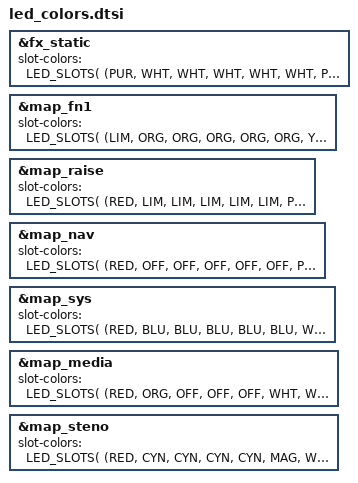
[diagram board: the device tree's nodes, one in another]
/*
 * Cores de cada LED em cada camada (zmk-rgb-matrix, efeito "static").
 *
 * Este arquivo e incluido no final de corne.keymap. Cada bloco "&map_<camada>"
 * preenche o slot-colors do efeito static de uma camada: o de um overlay de
 * camada (FN1 a STENO, cobrem os 27 LEDs de cada metade enquanto a camada esta
 * ativa) ou o do efeito fx_static (mapa da camada base, QWERTY). A estrutura
 * (overlays, condicoes, efeitos e o layer-id de cada mapa) fica em
 * corne.keymap; aqui ficam so as cores.
 *
 * Estas sao as cores PADRAO, as que o firmware tem de fabrica. O firmware
 * deixa editar e salvar as cores de cada slot no teclado (ZMK Studio, com o
 * fork lenerdz/zmk-studio-messages): o que for salvo vale no lugar destas, so
 * nos slots alterados, e RGB_RESET volta tudo para o que esta escrito aqui.
 *
 * COMO EDITAR
 *   Troque o nome da cor de uma posicao. Cada metade tem 3 linhas de 6 teclas,
 *   os 3 polegares e os 6 LEDs de underglow, nesta ordem:
 *
 *     esquerda:   0  1  2  3  4  5       direita:   6  7  8  9 10 11
 *                12 13 14 15 16 17                 18 19 20 21 22 23
 *                24 25 26 27 28 29                 30 31 32 33 34 35
 *                         36 37 38                 39 40 41
 *
 *   OFF apaga o LED. O comentario ao lado de cada linha diz que tecla era
 *   aquela no keymap quando o mapa foi escrito (se mudar a tecla, atualize a
 *   cor e o comentario).
 *
 * REGRAS
 *   - Dentro de LED_SLOTS(...) use so comentarios do tipo barra-asterisco. Um
 *     comentario de duas barras engole o resto da linha depois do pre-processador
 *     e apaga cores sem avisar.
 *   - O primeiro grupo e o das teclas da esquerda e o segundo o das teclas da
 *     direita. Os grupos tem sempre 27 valores (21 teclas + 6 de underglow).
 *   - As cores sao 0xRRGGBB com brilho cheio. O brilho real vem do kprgb
 *     (RGB_BRI e RGB_BRD, max-brightness) e vale para todas as cores igualmente.
 */

/*
 * Paleta. Para criar uma cor nova, acrescente uma linha (nome e 0xRRGGBB).
 */
#define OFF 0x000000 /* apagado */
#define WHT 0xFFFFFF /* branco */
#define RED 0xFF0000 /* vermelho */
#define ORG 0xFF8000 /* laranja */
#define YEL 0xFFFF00 /* amarelo */
#define LIM 0x80FF00 /* verde-limao */
#define GRN 0x00FF00 /* verde */
#define TEA 0x00FF80 /* verde-agua */
#define CYN 0x00FFFF /* ciano */
#define SKY 0x0080FF /* azul-claro */
#define BLU 0x0000FF /* azul */
#define PUR 0x8000FF /* roxo */
#define MAG 0xFF00FF /* magenta */
#define PNK 0xFF0080 /* rosa */

/*
 * Slots (a posicao de cada cor na lista slot-colors, 0 a 53). Sao os mesmos
 * nas duas metades, por isso a mesma lista vale para as duas:
 *   0 a 41  : a tecla de mesma posicao no keymap (k0 a k41)
 *   42 a 47 : underglow da esquerda (u0 a u5, na ordem da fita da esquerda)
 *   48 a 53 : underglow da direita (u0 a u5, na ordem da fita da direita)
 * "no-key-slots" e "slot-count" de corne_left.overlay e corne_right.overlay
 * dizem ao firmware qual LED usa qual slot.
 *
 * LED_SLOTS(esquerda, direita) recebe os dois grupos como estao escritos nos
 * blocos abaixo (cada um com 27 cores, na ordem dos parametros de
 * LED_SLOT_ORDER) e devolve as 54 cores na ordem dos slots.
 */
#define LED_UNPAREN(...) __VA_ARGS__
#define LED_APPLY(macro, ...) macro(__VA_ARGS__)
#define LED_SLOTS(left, right)                                                 \
    LED_APPLY(LED_SLOT_ORDER, LED_UNPAREN left, LED_UNPAREN right)

#define LED_SLOT_ORDER(                                                        \
    k0,  k1,  k2,  k3,  k4,  k5,                                               \
    k12, k13, k14, k15, k16, k17,                                              \
    k24, k25, k26, k27, k28, k29,                                              \
                   k36, k37, k38,                                              \
    l0,  l1,  l2,  l3,  l4,  l5,                                               \
    k6,  k7,  k8,  k9,  k10, k11,                                              \
    k18, k19, k20, k21, k22, k23,                                              \
    k30, k31, k32, k33, k34, k35,                                              \
    k39, k40, k41,                                                             \
    r0,  r1,  r2,  r3,  r4,  r5)                                               \
    k0  k1  k2  k3  k4  k5  k6  k7  k8  k9  k10 k11                            \
    k12 k13 k14 k15 k16 k17 k18 k19 k20 k21 k22 k23                            \
    k24 k25 k26 k27 k28 k29 k30 k31 k32 k33 k34 k35                            \
    k36 k37 k38 k39 k40 k41                                                    \
    l0  l1  l2  l3  l4  l5  r0  r1  r2  r3  r4  r5


/* Camada 0: QWERTY (destaque BLU) */
&fx_static {
    slot-colors = <LED_SLOTS(
        /* esquerda */
        (PUR, WHT, WHT, WHT, WHT, WHT, /* TAB Q W E R T */
         PUR, WHT, WHT, WHT, WHT, WHT, /* LSHFT A S D F G */
         PUR, WHT, WHT, WHT, WHT, WHT, /* LCTRL Z X C V B */
                        PUR, ORG, WHT, /* LGUI FN1 SPACE (polegares) */
         BLU, BLU, BLU, BLU, BLU, BLU)/* underglow */,

        /* direita */
        (WHT, WHT, WHT, WHT, WHT, RED, /* Y U I O P BSPC */
         WHT, WHT, WHT, WHT, LIM, LIM, /* H J K L SEMI SQT */
         WHT, WHT, LIM, LIM, SKY, SKY, /* N M COMMA DOT LBKT RBKT */
         TEA, SKY, PUR, /* RET RAISE RALT (polegares) */
         BLU, BLU, BLU, BLU, BLU, BLU)/* underglow */
    )>;
};

/* Camada 1: FN1 (destaque ORG) */
&map_fn1 {
    slot-colors = <LED_SLOTS(
        /* esquerda */
        (LIM, ORG, ORG, ORG, ORG, ORG, /* GRAVE F1 F2 F3 F4 F5 */
         YEL, YEL, YEL, YEL, YEL, YEL, /* N1 N2 N3 N4 N5 N6 */
         GRN, MAG, CYN, ORG, OFF, OFF, /* NAV SYS MEDIA F12 -- -- */
                        PUR, ORG, WHT, /* LGUI -- SPACE (polegares) */
         ORG, ORG, ORG, ORG, ORG, ORG)/* underglow */,

        /* direita */
        (ORG, ORG, ORG, ORG, ORG, ORG, /* F6 F7 F8 F9 F10 F11 */
         YEL, YEL, YEL, YEL, LIM, LIM, /* N7 N8 N9 N0 MINUS EQUAL */
         OFF, OFF, OFF, OFF, OFF, OFF, /* -- -- -- -- -- -- */
         TEA, SKY, PUR, /* RET -- RALT (polegares) */
         ORG, ORG, ORG, ORG, ORG, ORG)/* underglow */
    )>;
};

/* Camada 2: RAISE (destaque SKY) */
&map_raise {
    slot-colors = <LED_SLOTS(
        /* esquerda */
        (RED, LIM, LIM, LIM, LIM, LIM, /* ESC EXCL AT HASH DLLR PRCNT */
         PUR, MAG, LIM, LIM, LIM, LIM, /* LCTRL STUDIO FSLH BSLH GRAVE TILDE */
         PUR, OFF, OFF, OFF, OFF, OFF, /* LSHFT -- -- -- -- -- */
                        PUR, ORG, WHT, /* LGUI -- SPACE (polegares) */
         SKY, SKY, SKY, SKY, SKY, SKY)/* underglow */,

        /* direita */
        (LIM, LIM, LIM, SKY, SKY, RED, /* CARET AMPS ASTRK LPAR RPAR BSPC */
         LIM, LIM, SKY, SKY, SKY, SKY, /* MINUS EQUAL LBKT RBKT LBRC RBRC */
         LIM, LIM, LIM, LIM, LIM, LIM, /* UNDER PLUS PIPE COLON DQT QMARK */
         TEA, SKY, PUR, /* RET -- RALT (polegares) */
         SKY, SKY, SKY, SKY, SKY, SKY)/* underglow */
    )>;
};

/* Camada 3: NAV (destaque GRN) */
&map_nav {
    slot-colors = <LED_SLOTS(
        /* esquerda */
        (RED, OFF, OFF, OFF, OFF, OFF, /* ESC -- -- -- -- -- */
         PUR, LIM, LIM, LIM, LIM, ORG, /* LCTRL HOME PG_DN PG_UP END INS */
         GRN, MAG, CYN, OFF, OFF, OFF, /* LSHFT -- -- -- -- -- */
                        PUR, ORG, WHT, /* LGUI -- SPACE (polegares) */
         GRN, GRN, GRN, GRN, GRN, GRN)/* underglow */,

        /* direita */
        (OFF, OFF, OFF, OFF, OFF, RED, /* -- -- -- -- -- BSPC */
         GRN, GRN, GRN, GRN, PUR, RED, /* LEFT DOWN UP RIGHT TAB DEL */
         LIM, LIM, LIM, LIM, OFF, OFF, /* HOME PG_DN PG_UP END -- -- */
         TEA, SKY, PUR, /* RET -- RALT (polegares) */
         GRN, GRN, GRN, GRN, GRN, GRN)/* underglow */
    )>;
};

/* Camada 4: SYS (destaque MAG) */
&map_sys {
    slot-colors = <LED_SLOTS(
        /* esquerda */
        (RED, BLU, BLU, BLU, BLU, BLU, /* BT_CLR BT0 BT1 BT2 BT3 BT4 */
         WHT, PNK, ORG, ORG, YEL, YEL, /* RGB_TOG RGB_EFF RGB_HUI RGB_HUD RGB_BRI RGB_BRD */
         MAG, MAG, TEA, TEA, TEA, TEA, /* STUDIO -- ug_rain ug_brth ug_spec ug_star */
                        PUR, ORG, WHT, /* LGUI -- SPACE (polegares) */
         MAG, MAG, MAG, MAG, MAG, MAG)/* underglow */,

        /* direita */
        (PNK, PNK, PNK, PNK, PNK, PNK, /* solid breathe spectrum rainbow reactive ripple */
         PNK, LIM, LIM, CYN, CYN, RED, /* RGB_EFR RGB_SAI RGB_SAD RGB_SPI RGB_SPD RGB_RESET */
         PNK, PNK, PNK, PUR, WHT, WHT, /* heatmap starlight static steno_on TO6 ug_off */
         TEA, SKY, PUR, /* RET -- RALT (polegares) */
         MAG, MAG, MAG, MAG, MAG, MAG)/* underglow */
    )>;
};

/* Camada 5: MEDIA (destaque CYN) */
&map_media {
    slot-colors = <LED_SLOTS(
        /* esquerda */
        (RED, ORG, OFF, OFF, OFF, WHT, /* C_PWR C_SLEEP -- -- -- CAPS_WORD */
         WHT, CYN, CYN, YEL, YEL, WHT, /* C_MUTE C_VOL_DN C_VOL_UP C_BRI_DN C_BRI_UP CAPS */
         GRN, MAG, CYN, OFF, OFF, OFF, /* -- -- -- -- -- -- */
                        PUR, ORG, WHT, /* LGUI -- SPACE (polegares) */
         CYN, CYN, CYN, CYN, CYN, CYN)/* underglow */,

        /* direita */
        (OFF, OFF, OFF, OFF, LIM, LIM, /* -- -- -- -- PSCRN SLCK */
         GRN, TEA, GRN, ORG, OFF, OFF, /* C_PREV C_PP C_NEXT C_STOP -- -- */
         OFF, OFF, OFF, OFF, OFF, OFF, /* -- -- -- -- -- -- */
         TEA, SKY, PUR, /* RET -- RALT (polegares) */
         CYN, CYN, CYN, CYN, CYN, CYN)/* underglow */
    )>;
};

/* Camada 6: STENO (destaque PUR) */
&map_steno {
    slot-colors = <LED_SLOTS(
        /* esquerda */
        (RED, CYN, CYN, CYN, CYN, MAG, /* steno_off Q W E R T */
         WHT, CYN, CYN, CYN, CYN, MAG, /* TO0 A S D F G */
         OFF, OFF, OFF, OFF, OFF, OFF, /* -- -- -- -- -- -- */
                        YEL, GRN, GRN, /* N1 C V (polegares) */
         PUR, PUR, PUR, PUR, PUR, PUR)/* underglow */,

        /* direita */
        (MAG, ORG, ORG, ORG, ORG, ORG, /* Y U I O P LBKT */
         MAG, ORG, ORG, ORG, ORG, ORG, /* H J K L SEMI SQT */
         OFF, OFF, OFF, OFF, OFF, OFF, /* -- -- -- -- -- -- */
         GRN, GRN, YEL, /* N M N0 (polegares) */
         PUR, PUR, PUR, PUR, PUR, PUR)/* underglow */
    )>;
};
